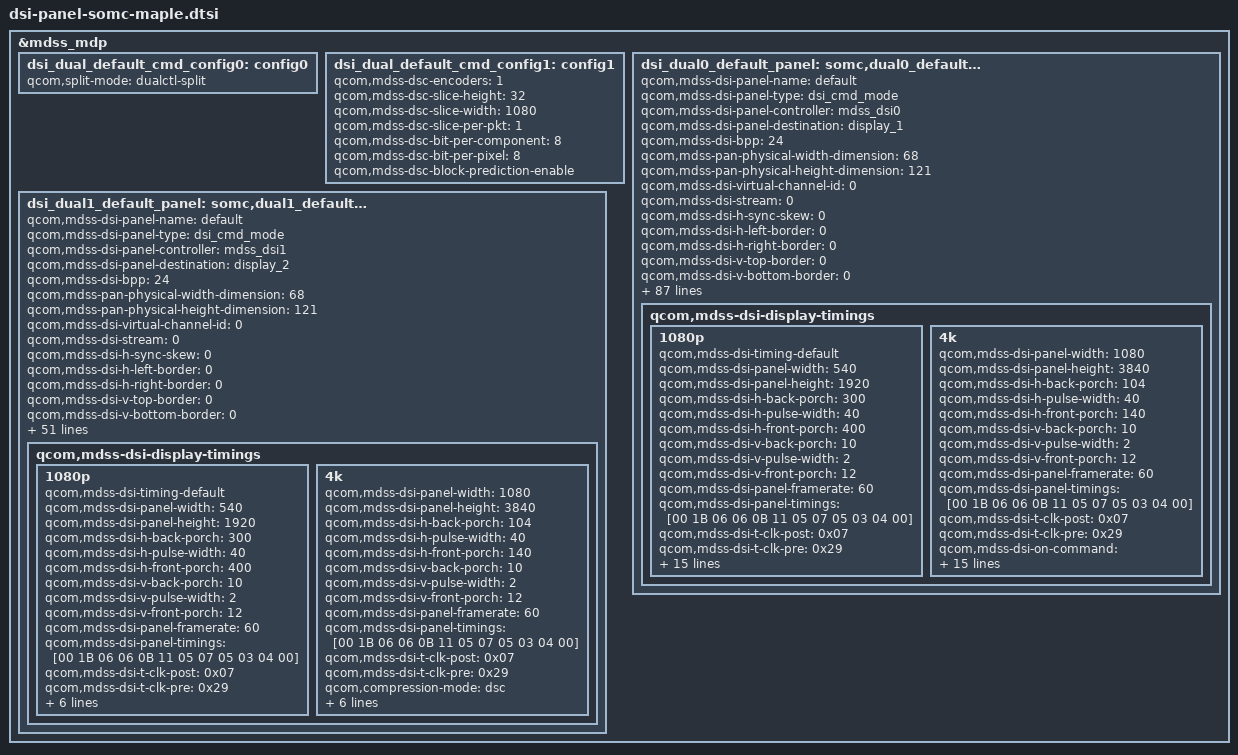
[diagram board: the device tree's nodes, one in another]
/* arch/arm64/boot/dts/qcom/dsi-panel-maple.dtsi
 *
 * This program is free software; you can redistribute it and/or modify
 * it under the terms of the GNU General Public License version 2 and
 * only version 2 as published by the Free Software Foundation.
 *
 * This program is distributed in the hope that it will be useful,
 * but WITHOUT ANY WARRANTY; without even the implied warranty of
 * MERCHANTABILITY or FITNESS FOR A PARTICULAR PURPOSE.  See the
 * GNU General Public License for more details.
 */
/*
 * Copyright (C) 2016 Sony Mobile Communications Inc.
 *
 * This program is free software; you can redistribute it and/or modify
 * it under the terms of the GNU General Public License version 2, as
 * published by the Free Software Foundation.
 */

#include "dsi-panel-somc-synaptics-sharp-4k-cmd-ID3.dtsi"
#include "dsi-panel-somc-synaptics-sharp-4k-cmd-ID6.dtsi"

&mdss_mdp {
	dsi_dual_default_cmd_config0: config0 {
		qcom,split-mode = "dualctl-split";
	};

	dsi_dual_default_cmd_config1: config1 {
		qcom,mdss-dsc-encoders = <1>;
		qcom,mdss-dsc-slice-height = <32>;
		qcom,mdss-dsc-slice-width = <1080>;
		qcom,mdss-dsc-slice-per-pkt = <1>;
		qcom,mdss-dsc-bit-per-component = <8>;
		qcom,mdss-dsc-bit-per-pixel = <8>;
		qcom,mdss-dsc-block-prediction-enable;
	};

	/* Default */
	dsi_dual0_default_panel: somc,dual0_default_panel {
		qcom,mdss-dsi-panel-name = "default";
		qcom,mdss-dsi-panel-type = "dsi_cmd_mode";
		qcom,mdss-dsi-panel-controller = <&mdss_dsi0>;
		qcom,mdss-dsi-panel-destination = "display_1";
		qcom,mdss-dsi-bpp = <24>;
		qcom,mdss-pan-physical-width-dimension = <68>;
		qcom,mdss-pan-physical-height-dimension = <121>;
		qcom,mdss-dsi-virtual-channel-id = <0>;
		qcom,mdss-dsi-stream = <0>;
		qcom,mdss-dsi-h-sync-skew = <0>;
		qcom,mdss-dsi-h-left-border = <0>;
		qcom,mdss-dsi-h-right-border = <0>;
		qcom,mdss-dsi-v-top-border = <0>;
		qcom,mdss-dsi-v-bottom-border = <0>;
		qcom,mdss-dsi-underflow-color = <0x0>;
		qcom,mdss-dsi-border-color = <0>;
		qcom,mdss-dsi-h-sync-pulse = <1>;
		qcom,mdss-dsi-traffic-mode = "non_burst_sync_event";
		qcom,mdss-dsi-bllp-eof-power-mode;
		qcom,mdss-dsi-bllp-power-mode;
		qcom,mdss-dsi-dma-trigger = "trigger_sw";
		qcom,mdss-dsi-mdp-trigger = "none";
		qcom,mdss-dsi-tx-eot-append;
		qcom,mdss-dsi-off-command = [
					05 01 00 00 0A 00 01 28
					05 01 00 00 96 00 01 10];
		qcom,mdss-dsi-off-command-state = "dsi_hs_mode";
		qcom,mdss-dsi-te-pin-select = <1>;
		qcom,mdss-dsi-wr-mem-start = <0x2c>;
		qcom,mdss-dsi-wr-mem-continue = <0x3c>;
		qcom,mdss-dsi-te-dcs-command = <1>;
		qcom,mdss-dsi-te-check-enable;
		qcom,mdss-dsi-te-using-te-pin;
		qcom,mdss-dsi-lane-0-state;
		qcom,mdss-dsi-lane-1-state;
		qcom,mdss-dsi-lane-2-state;
		qcom,mdss-dsi-lane-3-state;
		qcom,panel-supply-entries = <&dsi_panel_pwr_supply_hybrid_incell>;
		qcom,mdss-dsi-lp11-init;
		qcom,mdss-dsi-bl-min-level = <1>;
		qcom,mdss-dsi-bl-max-level = <4095>;
		qcom,mdss-brightness-max-level = <4095>;
		qcom,mdss-dsi-bl-pmic-control-type = "bl_ctrl_wled";

		qcom,mdss-dsi-panel-hdr-enabled;
		qcom,mdss-dsi-panel-hdr-color-primaries = <14940 15790 33800 15700 10950 33800 7450 2300>;
		qcom,mdss-dsi-panel-peak-brightness = <7000000>;
		qcom,mdss-dsi-panel-blackness-level = <4646>;

		somc,dsi-index = <0>;
		somc,lcd-id = <0>;
		somc,lcd-id-adc = <0 0x7fffffff>;

		somc,pw-on-rst-seq = <0 15>, <1 10>, <0 15>, <1 20>;
		somc,pw-off-rst-b-seq = <0 11>;
		somc,pw-wait-after-on-vdd = <0>;
		somc,pw-wait-after-on-vddio = <10>;
		somc,pw-wait-after-on-vsp = <0>;
		somc,pw-wait-after-on-vsn = <0>;
		somc,pw-wait-after-on-dcdc = <10>;
		somc,pw-wait-after-off-vdd = <0>;
		somc,pw-wait-after-off-vddio = <1>;
		somc,pw-wait-after-off-vsp = <5>;
		somc,pw-wait-after-off-vsn = <5>;
		somc,pw-wait-after-off-dcdc = <5>;
		somc,pw-wait-after-on-touch-avdd = <1>;
		somc,pw-wait-after-on-touch-vddio = <0>;
		somc,pw-wait-after-on-touch-reset = <0>;
		somc,pw-wait-after-on-touch-int-n = <10>;
		somc,pw-wait-after-off-touch-avdd = <0>;
		somc,pw-wait-after-off-touch-vddio = <0>;
		somc,pw-wait-after-off-touch-reset = <0>;
		somc,pw-wait-after-off-touch-int-n = <0>;
		somc,pw-down-period = <100>;

		somc,lab-output-voltage = <5800000>;
		somc,ibb-output-voltage = <5600000>;
		somc,qpnp-lab-limit-maximum-current = <200>;
		somc,qpnp-ibb-limit-maximum-current = <800>;
		somc,qpnp-lab-max-precharge-time = <500>;
		somc,qpnp-lab-soft-start = <800>;
		somc,qpnp-ibb-discharge-resistor = <300>;
		somc,qpnp-lab-pull-down-enable;
		somc,qpnp-lab-full-pull-down;
		somc,qpnp-ibb-pull-down-enable;
		somc,qpnp-ibb-full-pull-down;

		somc,ewu-wait-after-touch-reset = <40>;
		somc,lk-on-skip;

		qcom,esd-check-enabled;
		qcom,mdss-dsi-panel-status-command = [06 01 00 01 05 00 01 0A];
		qcom,mdss-dsi-panel-status-command-state = "dsi_lp_mode";
		qcom,mdss-dsi-panel-status-check-mode = "reg_read";
		qcom,mdss-dsi-panel-status-read-length = <1>;
		qcom,mdss-dsi-panel-max-error-count = <3>;
		qcom,mdss-dsi-panel-status-value = <0x9c>;

		qcom,dynamic-mode-switch-enabled;
		qcom,dynamic-mode-switch-type = "dynamic-resolution-switch-immediate";
		qcom,dcs-cmd-by-left;
		qcom,mdss-dsi-display-timings {
			1080p {
				qcom,mdss-dsi-timing-default;
				qcom,mdss-dsi-panel-width = <540>;
				qcom,mdss-dsi-panel-height = <1920>;
				qcom,mdss-dsi-h-back-porch = <300>;
				qcom,mdss-dsi-h-pulse-width = <40>;
				qcom,mdss-dsi-h-front-porch = <400>;
				qcom,mdss-dsi-v-back-porch = <10>;
				qcom,mdss-dsi-v-pulse-width = <2>;
				qcom,mdss-dsi-v-front-porch = <12>;
				qcom,mdss-dsi-panel-framerate = <60>;
				qcom,mdss-dsi-panel-timings = [00 1B 06 06 0B 11 05 07 05 03 04 00];
				qcom,mdss-dsi-t-clk-post = <0x07>;
				qcom,mdss-dsi-t-clk-pre = <0x29>;
				qcom,mdss-dsi-on-command = [
							39 01 00 00 00 00 06 F0 55 AA 52 08 00
							15 01 00 00 00 00 02 C9 01
							15 01 00 00 00 00 02 90 00
							15 01 00 00 00 00 02 58 01
							39 01 00 00 00 00 06 F0 55 AA 52 08 07
							15 01 00 00 00 00 02 EF 01
							39 01 00 00 00 00 06 F0 55 AA 52 08 00
							15 01 00 00 00 00 02 B4 01
							39 01 00 00 00 00 10 BD 00 AC 0C 0C 00 01 56 09 09 01 01 0C 0C 00 D9
							15 01 00 00 00 00 02 35 00
							39 01 00 00 00 00 03 44 00 00
							39 01 00 00 00 00 06 F0 55 AA 52 08 01
							39 01 00 00 00 00 03 D4 88 88
							39 01 00 00 00 00 05 FF AA 55 A5 80
							15 01 00 00 00 00 02 6F 01
							15 01 00 00 00 00 02 F3 10
							39 01 00 00 00 00 05 FF AA 55 A5 00];
				qcom,mdss-dsi-post-panel-on-command  = [
							05 01 00 00 00 00 01 29
							05 01 00 00 43 00 01 11];

				qcom,mdss-dsi-on-command-state = "dsi_lp_mode";

				qcom,mdss-dsi-timing-switch-command = [
							39 00 00 00 00 00 06 F0 55 AA 52 08 00
							15 00 00 00 00 00 02 C9 01
							15 00 00 00 00 00 02 90 00
							15 00 00 00 00 00 02 58 01
							15 00 00 00 00 00 02 03 00
							39 00 00 00 00 00 06 F0 55 AA 52 08 04
							15 01 00 00 00 00 02 C0 03
							];
				qcom,mdss-dsi-timing-switch-command-state =
					"dsi_lp_mode";

				qcom,mdss-tear-check-sync-init-val = <3840>;
				qcom,mdss-tear-check-start-pos = <3840>;
				qcom,mdss-tear-check-rd-ptr-trigger-intr = <3841>;

				qcom,config-select = <&dsi_dual_default_cmd_config0>;

				qcom,mdss-dsi-panel-clockrate = <899000000>;
			};

			4k {
				qcom,mdss-dsi-panel-width = <1080>;
				qcom,mdss-dsi-panel-height = <3840>;
				qcom,mdss-dsi-h-back-porch = <104>;
				qcom,mdss-dsi-h-pulse-width = <40>;
				qcom,mdss-dsi-h-front-porch = <140>;
				qcom,mdss-dsi-v-back-porch = <10>;
				qcom,mdss-dsi-v-pulse-width = <2>;
				qcom,mdss-dsi-v-front-porch = <12>;
				qcom,mdss-dsi-panel-framerate = <60>;
				qcom,mdss-dsi-panel-timings = [00 1B 06 06 0B 11 05 07 05 03 04 00];
				qcom,mdss-dsi-t-clk-post = <0x07>;
				qcom,mdss-dsi-t-clk-pre = <0x29>;
				qcom,mdss-dsi-on-command = [
							15 01 00 00 00 00 02 90 03
							15 01 00 00 00 00 02 03 01
							39 01 00 00 00 00 06 F0 55 AA 52 08 04
							15 01 00 00 00 00 02 C0 03
							39 01 00 00 00 00 06 F0 55 AA 52 08 07
							15 01 00 00 00 00 02 EF 01
							39 01 00 00 00 00 06 F0 55 AA 52 08 00
							15 01 00 00 00 00 02 B4 01
							15 01 00 00 00 00 02 35 00
							39 01 00 00 00 00 03 44 00 00
							39 01 00 00 00 00 06 F0 55 AA 52 08 01
							39 01 00 00 00 00 03 D4 88 88
							39 01 00 00 00 00 05 FF AA 55 A5 80
							15 01 00 00 00 00 02 6F 01
							15 01 00 00 00 00 02 F3 10
							39 01 00 00 00 00 05 FF AA 55 A5 00];
				qcom,mdss-dsi-post-panel-on-command  = [
							05 01 00 00 00 00 01 29
							05 01 00 00 43 00 01 11];
				qcom,mdss-dsi-on-command-state = "dsi_lp_mode";

				qcom,mdss-dsi-timing-switch-command = [
							39 00 00 00 00 00 06 F0 55 AA 52 08 00
							15 00 00 00 00 00 02 C9 01
							15 00 00 00 00 00 02 90 03
							15 00 00 00 00 00 02 58 00
							15 00 00 00 00 00 02 03 01
							39 00 00 00 00 00 06 F0 55 AA 52 08 04
							15 01 00 00 00 00 02 C0 03
							];
				qcom,mdss-dsi-timing-switch-command-state =
					"dsi_lp_mode";

				qcom,compression-mode = "dsc";
				qcom,config-select = <&dsi_dual_default_cmd_config1>;

				qcom,mdss-tear-check-sync-init-val = <3840>;
				qcom,mdss-tear-check-start-pos = <3840>;
				qcom,mdss-tear-check-rd-ptr-trigger-intr = <3841>;

				qcom,mdss-dsi-panel-clockrate = <899000000>;
			};
		};
	};

	dsi_dual1_default_panel: somc,dual1_default_panel {
		qcom,mdss-dsi-panel-name = "default";
		qcom,mdss-dsi-panel-type = "dsi_cmd_mode";
		qcom,mdss-dsi-panel-controller = <&mdss_dsi1>;
		qcom,mdss-dsi-panel-destination = "display_2";
		qcom,mdss-dsi-bpp = <24>;
		qcom,mdss-pan-physical-width-dimension = <68>;
		qcom,mdss-pan-physical-height-dimension = <121>;
		qcom,mdss-dsi-virtual-channel-id = <0>;
		qcom,mdss-dsi-stream = <0>;
		qcom,mdss-dsi-h-sync-skew = <0>;
		qcom,mdss-dsi-h-left-border = <0>;
		qcom,mdss-dsi-h-right-border = <0>;
		qcom,mdss-dsi-v-top-border = <0>;
		qcom,mdss-dsi-v-bottom-border = <0>;
		qcom,mdss-dsi-underflow-color = <0x0>;
		qcom,mdss-dsi-border-color = <0>;
		qcom,mdss-dsi-h-sync-pulse = <1>;
		qcom,mdss-dsi-traffic-mode = "non_burst_sync_event";
		qcom,mdss-dsi-bllp-eof-power-mode;
		qcom,mdss-dsi-bllp-power-mode;
		qcom,mdss-dsi-dma-trigger = "trigger_sw";
		qcom,mdss-dsi-mdp-trigger = "none";
		qcom,mdss-dsi-tx-eot-append;
		qcom,mdss-dsi-te-pin-select = <1>;
		qcom,mdss-dsi-wr-mem-start = <0x2c>;
		qcom,mdss-dsi-wr-mem-continue = <0x3c>;
		qcom,mdss-dsi-te-dcs-command = <1>;
		qcom,mdss-dsi-te-check-enable;
		qcom,mdss-dsi-te-using-te-pin;
		qcom,mdss-dsi-lane-0-state;
		qcom,mdss-dsi-lane-1-state;
		qcom,mdss-dsi-lane-2-state;
		qcom,mdss-dsi-lane-3-state;
		qcom,panel-supply-entries = <&dsi_panel_pwr_supply_hybrid_incell>;
		qcom,mdss-dsi-lp11-init;
		qcom,mdss-dsi-bl-min-level = <1>;
		qcom,mdss-dsi-bl-max-level = <4095>;
		qcom,mdss-brightness-max-level = <4095>;

		qcom,mdss-dsi-panel-hdr-enabled;
		qcom,mdss-dsi-panel-hdr-color-primaries = <14940 15790 33800 15700 10950 33800 7450 2300>;
		qcom,mdss-dsi-panel-peak-brightness = <7000000>;
		qcom,mdss-dsi-panel-blackness-level = <4646>;

		somc,dsi-index = <1>;
		somc,lcd-id = <0>;
		somc,lcd-id-adc = <0 0x7fffffff>;

		somc,lab-output-voltage = <5800000>;
		somc,ibb-output-voltage = <5600000>;
		somc,qpnp-lab-limit-maximum-current = <200>;
		somc,qpnp-ibb-limit-maximum-current = <800>;
		somc,qpnp-lab-max-precharge-time = <500>;
		somc,qpnp-lab-soft-start = <800>;
		somc,qpnp-ibb-discharge-resistor = <300>;
		somc,qpnp-lab-pull-down-enable;
		somc,qpnp-lab-full-pull-down;
		somc,qpnp-ibb-pull-down-enable;
		somc,qpnp-ibb-full-pull-down;

		somc,mdss-dsi-slave;
		somc,lk-on-skip;

		qcom,dynamic-mode-switch-enabled;
		qcom,dynamic-mode-switch-type = "dynamic-resolution-switch-immediate";
		qcom,dcs-cmd-by-left;
		qcom,mdss-dsi-display-timings {
			1080p {
				qcom,mdss-dsi-timing-default;
				qcom,mdss-dsi-panel-width = <540>;
				qcom,mdss-dsi-panel-height = <1920>;
				qcom,mdss-dsi-h-back-porch = <300>;
				qcom,mdss-dsi-h-pulse-width = <40>;
				qcom,mdss-dsi-h-front-porch = <400>;
				qcom,mdss-dsi-v-back-porch = <10>;
				qcom,mdss-dsi-v-pulse-width = <2>;
				qcom,mdss-dsi-v-front-porch = <12>;
				qcom,mdss-dsi-panel-framerate = <60>;
				qcom,mdss-dsi-panel-timings = [00 1B 06 06 0B 11 05 07 05 03 04 00];
				qcom,mdss-dsi-t-clk-post = <0x07>;
				qcom,mdss-dsi-t-clk-pre = <0x29>;

				qcom,mdss-tear-check-sync-init-val = <3840>;
				qcom,mdss-tear-check-start-pos = <3840>;
				qcom,mdss-tear-check-rd-ptr-trigger-intr = <3841>;

				qcom,config-select = <&dsi_dual_default_cmd_config0>;

				qcom,mdss-dsi-panel-clockrate = <899000000>;
			};

			4k {
				qcom,mdss-dsi-panel-width = <1080>;
				qcom,mdss-dsi-panel-height = <3840>;
				qcom,mdss-dsi-h-back-porch = <104>;
				qcom,mdss-dsi-h-pulse-width = <40>;
				qcom,mdss-dsi-h-front-porch = <140>;
				qcom,mdss-dsi-v-back-porch = <10>;
				qcom,mdss-dsi-v-pulse-width = <2>;
				qcom,mdss-dsi-v-front-porch = <12>;
				qcom,mdss-dsi-panel-framerate = <60>;
				qcom,mdss-dsi-panel-timings = [00 1B 06 06 0B 11 05 07 05 03 04 00];
				qcom,mdss-dsi-t-clk-post = <0x07>;
				qcom,mdss-dsi-t-clk-pre = <0x29>;

				qcom,compression-mode = "dsc";
				qcom,config-select = <&dsi_dual_default_cmd_config1>;

				qcom,mdss-tear-check-sync-init-val = <3840>;
				qcom,mdss-tear-check-start-pos = <3840>;
				qcom,mdss-tear-check-rd-ptr-trigger-intr = <3841>;

				qcom,mdss-dsi-panel-clockrate = <899000000>;
			};
		};
	};
};
